# USB0_COMMON_0_VBP2APB_WRAP_CONTROLLER_VBP_CORE_ADDR_MAP register map
Vendor: Texas Instruments
Registers are 32-bit, access per field, reset 0x0 unless marked. A register's access mark holds for its fields unless they carry their own. Offsets are as the file gives them; [hi:lo] are bit positions.

## USB0_COMMON_0_VBP2APB_WRAP_CONTROLLER_VBP_CORE_ADDR_MAP (part 6 of 8)
0x1EC VBP2APB_WRAP__CONTROLLER_VBP__CORE_ADDR_MAP_cfg_reg52 reset 0x16000
  [16:0] TWTREV_CNT rw — TWTREV: Time a high-speed capable device operating in high-speed must wait after start of SE0 before reverting to full-speed. Resolution of this parameter is 33.3 ns. For simulation purposes it is recommended to set the value 90112 [~3ms] For synthesis purposes it is recommended to set the value 90112 [~3ms]
0x1F0 VBP2APB_WRAP__CONTROLLER_VBP__CORE_ADDR_MAP_cfg_reg53 reset 0x5C00
  [14:0] TWTRSTHS_CNT rw — TWTRSTHS: Time a device must wait after reverting to full-speed before sampling the bus state for SE0 and beginning the high-speed detection handshake. Resolution of this parameter is 33.3 ns. For simulation purposes it is recommended to set the value 23552 [~785us] For synthesis purposes it is recommended to set the value 23552 [~785us]
0x1F4 VBP2APB_WRAP__CONTROLLER_VBP__CORE_ADDR_MAP_cfg_reg54 reset 0x24A00
  [17:0] TWTRSM_CNT rw — TWTRSM: Period of idle bus before device can initiate resume. Resolution of this parameter is 33.3 ns. For simulation purposes it is recommended to set the value 150016 [~5ms] For synthesis purposes it is recommended to set the value 150016 [~5ms]
0x1F8 VBP2APB_WRAP__CONTROLLER_VBP__CORE_ADDR_MAP_cfg_reg55 reset 0x8000
  [15:0] TDRSMUP_CNT rw — TDRSMUP: Duration of driving resume upstream. Resolution of this parameter is 33.3 ns. For simulation purposes it is recommended to set the value 32768 [~1.1ms] For synthesis purposes it is recommended to set the value 32768 [~1.1ms]
0x1FC VBP2APB_WRAP__CONTROLLER_VBP__CORE_ADDR_MAP_cfg_reg56 reset 0x30
  [5:0] TOUTHS_CNT rw — Time after device expecting a response to a transmission will timeout the transaction. Resolution of this parameter is 33.3 ns. For simulation purposes it is recommended to set the value 48 [~1.6us] For synthesis purposes it is recommended to set the value 48 [~1.6us]
0x200 VBP2APB_WRAP__CONTROLLER_VBP__CORE_ADDR_MAP_cfg_reg57 reset 0x2
  [1:0] LFPS_DEB_WIDTH rw — LFPS_DEB_WIDTH value This parameter defines the LFPS debouncer delay. Only two values are allowed: 0x1 or 0x2. For simulation purposes it is recommended to set the value 1. For synthesis purposes it is recommended to set the value 2.
0x204 VBP2APB_WRAP__CONTROLLER_VBP__CORE_ADDR_MAP_cfg_reg58 reset 0x3D090
  [17:0] LFPS_GEN_U2EXIT rw — LFPS_GEN_U2EXIT value Resolution of this parameter is 8 ns. For simulation purposes it is recommended to set the value 62500 [~500us] For synthesis purposes it is recommended to set the value 250000 [~2ms]
0x208 VBP2APB_WRAP__CONTROLLER_VBP__CORE_ADDR_MAP_cfg_reg59 reset 0x30D4
  [15:0] LFPS_MIN_GEN_U3EXIT rw — LFPS_MIN_GEN_U3EXIT value Resolution of this parameter is 8 ns. For simulation purposes it is recommended to set the value 12500 [~100us] For synthesis purposes it is recommended to set the value 12500 [~100us]
0x20C VBP2APB_WRAP__CONTROLLER_VBP__CORE_ADDR_MAP_cfg_reg60 reset 0x15
  [6:0] PORT_CONFIG_TIMEOUT rw — PORT_CONFIG_TIMEOUT value Resolution of this parameter is 1 us. For simulation purposes it is recommended to set the value 21 [~20us] For synthesis purposes it is recommended to set the value 21 [~20us]
0x210 VBP2APB_WRAP__CONTROLLER_VBP__CORE_ADDR_MAP_cfg_reg61 reset 0xFA
  [10:0] LFPS_POL_LFPS_TO_RXEQ rw — LFPS_POL_LFPS_TO_RXEQ value Resolution of this parameter is 8 ns. For simulation purposes it is recommended to set the value 250 [~2us] For synthesis purposes it is recommended to set the value 250 [~2us]
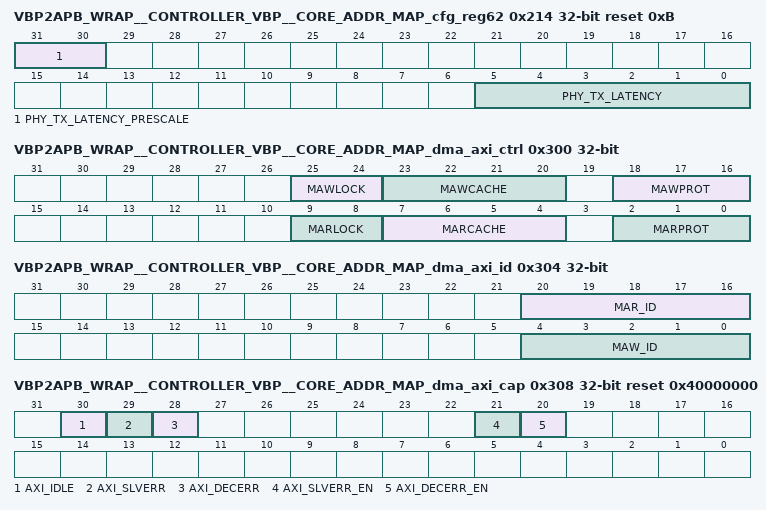
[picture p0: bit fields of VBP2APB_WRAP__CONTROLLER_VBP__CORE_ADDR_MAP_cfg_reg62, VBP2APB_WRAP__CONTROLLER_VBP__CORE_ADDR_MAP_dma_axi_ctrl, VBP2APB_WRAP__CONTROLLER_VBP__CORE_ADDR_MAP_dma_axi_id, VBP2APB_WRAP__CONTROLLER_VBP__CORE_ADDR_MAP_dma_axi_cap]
0x214 VBP2APB_WRAP__CONTROLLER_VBP__CORE_ADDR_MAP_cfg_reg62 reset 0xB
  [31:30] PHY_TX_LATENCY_PRESCALE rw — PRESCALER for PHY_TX_LATENCY value: - 0x0 : 8ns [PHY pclk clock] - 0x1 : 1us - 0x2 : 100us - 0x3 : no clock - allows disabling certain timeout
  [5:0] PHY_TX_LATENCY rw — PHY_TX_LATENCY value This parameter defines latency from when data appear on PIPE interface to channel + 3 time units [defined by PHY_TX_LATENCY_PRESCALE]. For simulation purposes it is recommended to set the value 11. For synthesis purposes it is recommended to set the value 11
0x218 VBP2APB_WRAP__CONTROLLER_VBP__CORE_ADDR_MAP_cfg_reg63 reset 0x7CFF
  [14:0] U2_INACTIVITY_TMOUT rw — U2_INACTIVITY_TMOUT value Resolution of this parameter is 8 ns. For simulation purposes it is recommended to set the value: - 31999*8ns =~256us [SystemC device ENV] - 249*8ns =~2us [VIP based ENV] For synthesis purposes it is recommended to set the value: - 31999*8ns =~256us
0x220 VBP2APB_WRAP__CONTROLLER_VBP__CORE_ADDR_MAP_cfg_reg64 reset 0x4A
  [6:0] TFILTSE0 rw — TFILTSE0: Reset Handshake Protocol: Time for which a suspended highspeed capable device must see a continuous SE0 before beginning the high-speed detection handshake. Resolution of this parameter is 33.3ns. For simulation purposes it is recommended to set the value: - 74*33.3ns =~2.46us [SystemC device ENV] - 57*33.3ns =~1.9us [VIP based ENV] For synthesis purposes it is recommended to set the value: - 74*33.3ns =~2.46us
0x224 VBP2APB_WRAP__CONTROLLER_VBP__CORE_ADDR_MAP_cfg_reg65 reset 0x4B
  [6:0] TFILT rw — TFILT: Time for which a Chirp J or Chirp K must be continuously detected [filtered] by hub or device during Reset handshake. Resolution of this parameter is 33.3 ns. For simulation purposes it is recommended to set the value: - 75*33.3ns =~2.5us [SystemC device ENV] - 57*33.3ns =~1.9us [VIP based ENV] For synthesis purposes it is recommended to set the value: - 75*33.3ns =~2.5us
0x228 VBP2APB_WRAP__CONTROLLER_VBP__CORE_ADDR_MAP_cfg_reg66 reset 0x49
  [6:0] TWTRSTFS_SE0 rw — TWTRSTFS: Time a high-speed capable device operating in non-suspended fullspeed must wait after start of SE0 before beginning the high-speed detection handshake. Resolution of this parameter is 33.3 ns. For simulation purposes it is recommended to set the value: - 73*33.3ns =~2.43us [SystemC device ENV] - 57*33.3ns =~1.9us [VIP based ENV] For synthesis purposes it is recommended to set the value: - 73*33.3ns =~2.43us
0x300 VBP2APB_WRAP__CONTROLLER_VBP__CORE_ADDR_MAP_dma_axi_ctrl
  [25:24] MAWLOCK rw — The mawlock pin configuration
  [23:20] MAWCACHE rw — The mawcache pin configuration
  [18:16] MAWPROT rw — The mawprot pin configuration
  [9:8] MARLOCK rw — The marlock pin configuration
  [7:4] MARCACHE rw — The marcache pin configuration
  [2:0] MARPROT rw — The marprot pin configuration
0x304 VBP2APB_WRAP__CONTROLLER_VBP__CORE_ADDR_MAP_dma_axi_id
  [20:16] MAR_ID rw — The marid pin configuration
  [4:0] MAW_ID rw — The mawid and mwid pin configuration
0x308 VBP2APB_WRAP__CONTROLLER_VBP__CORE_ADDR_MAP_dma_axi_cap access not given reset 0x40000000
  [30] AXI_IDLE ro — This bit provides information about the AXI Master state: '1': no pending action required by the AXI Master wrapper, '0': the AXI Master wrapper has outstanding transactions.
  [29] AXI_SLVERR — This bit provides an information about AXI SLAVE ERROR response on B or R channel. This flag is cleared by writing '1' to it. Once set it is held until cleared. (access R/W1TC)
  [28] AXI_DECERR — This bit provides an information about AXI DECODE ERROR response on B or R channel. This flag is cleared by writing '1' to it. Once set it is held until cleared. (access R/W1TC)
  [21] AXI_SLVERR_EN rw — This bit enables interrupt on AXI SLAVE ERROR detection. When 1 and AXI_SLVERR is 1 then AXI SLAVE ERROR interrupt is requested. When 0 - disabled interrupt from this source
  [20] AXI_DECERR_EN rw — This bit enables interrupt on AXI DECODE ERROR detection. When 1 and AXI_DECERR is 1 then AXI DECODE ERROR interrupt is requested. When 0 - disabled interrupt from this source
0x30C VBP2APB_WRAP__CONTROLLER_VBP__CORE_ADDR_MAP_dma_axi_ctrl0 reset 0xF
  [3:0] B_MAX rw — The register controls maximum burst length - it is used by the AXI Master wrapper to determine maximum value of AxLEN. It uses AXI AxLEN encoding. Default value is the maximum supported one and it is implementation specific. Width of this register is the same as AxLEN signals width. Note: This register should only be written to during the register initialisation process
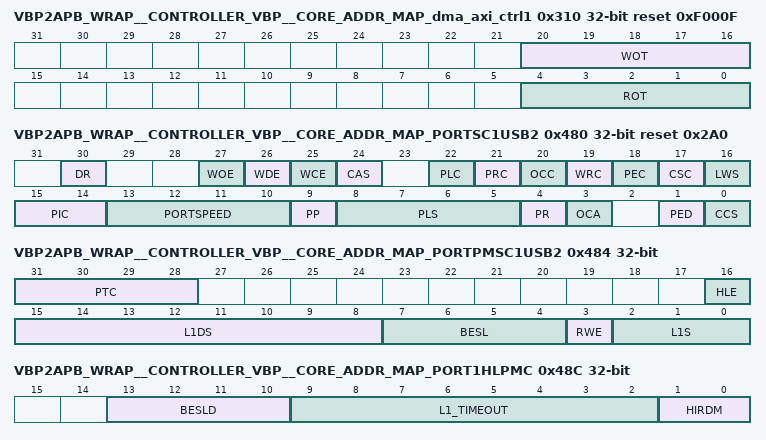
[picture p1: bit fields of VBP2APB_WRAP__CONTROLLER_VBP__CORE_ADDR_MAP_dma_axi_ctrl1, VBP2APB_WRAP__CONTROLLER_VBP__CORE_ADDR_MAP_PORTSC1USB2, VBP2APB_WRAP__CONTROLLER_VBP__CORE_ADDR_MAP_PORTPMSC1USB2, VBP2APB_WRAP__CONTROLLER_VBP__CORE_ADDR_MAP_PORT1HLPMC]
0x310 VBP2APB_WRAP__CONTROLLER_VBP__CORE_ADDR_MAP_dma_axi_ctrl1 reset 0xF000F
  [20:16] WOT rw — Number of outstanding write transactions that can be initiated by the AXI Master wrapper. Default value of this field is CDNS_USBSSDEV_AXI_WCD-1 [define parameter]. The value written to this field should be the requested number of outstanding write transactions minus 1, thus the actual number of possible outstanding write transactions is one more than the programmed value. Note: This register should only be written to during the register initialization process
  [4:0] ROT rw — Number of outstanding read transactions that can be initiated by the AXI Master wrapper. Default value of this field is CDNS_USBSSDEV_AXI_WCD-1 [define parameter]. The value written to this field should be the requested number of outstanding read transactions minus 1, thus the actual number of possible outstanding read transactions is one more than the programmed value. Note: This register should only be written to during the register initialization process
0x314 VBP2APB_WRAP__CONTROLLER_VBP__CORE_ADDR_MAP_dma_axi_ctrl2 reset 0x1
  [6:0] AXI_WTHRES rw — AXI Write Buffer Threshold, RW. When performing an AXI write burst this field specifies the minimum number of required AXI beats buffered prior to starting the burst on AXI W-Channel by asserting wvalid. This allows a user to balance the requirement for minimal latency with the requirement for low bus utilisation during bursts. Burst lengths smaller than or equal to this threshold will be buffered completely and then output on W-Channel. Burst lengths greater than this threshold will output the burst on the W-Channel such that the first AXI_WTHRES beats will be continuously with no drop of WVALID, beats thereafter may or may not be continuous depending on availability of data. Legal values are between 1 and 127. A value of 1 means that the burst is started on W-Channel as soon as any data is available without any additional delay. A value of 0 is reserved and should not be used as may lead to unpredictable behaviour. This register can be written only when the AXI Master wrapper is halted [AXI_HALT set to '1'] and idle [AXI_IDLE is '1']. Note: This register should only be written to during the register initialisation process.
0x480 VBP2APB_WRAP__CONTROLLER_VBP__CORE_ADDR_MAP_PORTSC1USB2 access not given reset 0x2A0
  [30] DR ro — Device Removable [DR], RO. This flag indicates if this port has a removable device attached. '0' = Device is removable. '1' = Device is non-removable.
  [27] WOE rw — Wake on Over-current Enable [WOE], RWS. Default = '0'. Writing this bit to a '1' enables the port to be sensitive to over-current conditions as system wake-up events. Refer to section 4.15 of xHCI specification for operational model.
  [26] WDE rw — Wake on Disconnect Enable [WDE], RWS. Default = '0'. Writing this bit to a '1' enables the port to be sensitive to device disconnects as system wake-up events. Refer to section 4.15 of xHCI specification for operational model.
  [25] WCE rw — Wake on Connect Enable [WCE], RWS. Default = '0'. Writing this bit to a '1' enables the port to be sensitive to device connects as system wake-up events. Refer to section 4.15 of xHCI specification for operational model.
  [24] CAS ro — Cold Attach Status [CAS], RO. Default = '0'. '1' = Far-end Receiver Terminations were detected in the Disconnected state and the Root Hub Port State Machine was unable to advance to the Enabled state. Refer to sections 4.19.8 of xHCI specification for more details on the Cold Attach Status [CAS] assertion conditions. Software shall clear this bit by writing a '1' to WPR or the xHC shall clear this bit if CCS transitions to '1'. This flag is '0' for USB2 protocol ports.
  [22] PLC — Port Link State Change [PLC], RW1CS. Default = '0'. This flag is set to '1' due to the following PLS transitions: U3 -> Resume [Wakeup signaling from a device], Resume -> Recovery -> U0 [Device Resume complete [USB3 protocol ports only]], Resume -> U0 [Device Resume complete [USB2 protocol ports only]], U3 -> Recovery -> U0 [Software Resume complete [USB3 protocol ports only]], U3 -> U0 [Software Resume complete [USB2 protocol ports only]], U2 -> U0 [L1 Resume complete [USB2 protocol ports only]], U0 -> U0 [L1 Entry Reject [USB2 protocol ports only]], Any state -> Inactive [Error [USB3 protocol ports only]]. Note that this flag shall not be set if the PLS transition was due to software setting PP to 0. Refer to section 4.23.5 of xHCI specification for more information. '0' = No change. '1' = Link Status Changed. Software shall clear this bit by writing a '1' to it. Refer to PLC Condition: references in section 4.19.1 for the specific port state transitions that set this flag. Refer to section 4.19.2 of xHCI specification for more information on change bit usage. (access R/W1TC)
  [21] PRC — Port Reset Change [PRC], RW1CS. Default = '0'. This flag is set to '1' due to a '1' to '0' transition of Port Reset [PR], e.g. when any reset processing [Warm or Hot] on this port is complete. Note that this flag shall not be set to '1' if the reset processing was forced to terminate due to software clearing PP or PED to '0'. '0' = No change. '1' = Reset complete. Software shall clear this bit by writing a '1' to it. Refer to section 4.19.5 of xHCI specification. Refer to section 4.19.2 of xHCI specification for more information on change bit usage. (access R/W1TC)
  [20] OCC — Over-current Change [OCC], RW1CS. Default = '0'. This bit shall be set to a '1' when there is a '0' to '1' or '1' to '0' transition of Over-current Active [OCA]. Software shall clear this bit by writing a '1' to it. Refer to section 4.19.2 of xHCI specification for more information on change bit usage. (access R/W1TC)
  [19] WRC — Warm Port Reset Change [WRC], RW1CS/RsvdZ. Default = '0'. This bit is set when Warm Reset processing on this port completes. '0' = No change. '1' = Warm Reset complete. Note that this flag shall not be set to '1' if the Warm Reset processing was forced to terminate due to software clearing PP or PED to '0'. Software shall clear this bit by writing a '1' to it. Refer to section 4.19.5.1 of xHCI specification. Refer to section 4.19.2 of xHCI specification for more information on change bit usage. This bit only applies to USB3 protocol ports. For USB2 protocol ports it shall be RsvdZ. (access R/W1TC)
  [18] PEC — Port Enabled/Disabled Change [PEC], RW1CS. Default = '0'. '1' = change in PED. '0' = No change. Note that this flag shall not be set if the PED transition was due to software setting PP to '0'. Software shall clear this bit by writing a '1' to it. Refer to section 4.19.2 of xHCI specification for more information on change bit usage. This bit shall be set to '1' only when the port is disabled due to the appropriate conditions existing at the EOF2 point [refer to section 11.8.1 of the USB2 Specification for the definition of a Port Error]. (access R/W1TC)
  [17] CSC — Connect Status Change [CSC], RW1CS. Default = '0'. '1' = Change in CCS. '0' = No change. This flag indicates a change has occurred in the ports Current Connect Status [CCS] or Cold Attach Status [CAS] bits. Note that this flag shall not be set if the CCS transition was due to software setting PP to '0', or the CAS transition was due to software setting WPR to '1'. The xHC sets this bit to '1' for all changes to the port device connect status, even if system software has not cleared an existing Connect Status Change. For example, the insertion status changes twice before system software has cleared the changed condition, root hub hardware will be setting an already-set bit [i.e., the bit will remain 1]. Software shall clear this bit by writing a '1' to it. Refer to section 4.19.2 of xHCI specification for more information on change bit usage. (access R/W1TC)
  [16] LWS rw — Port Link State Write Strobe [LWS], RW. Default = '0'. When this bit is set to '1' on a write reference to this register, this flag enables writes to the PLS field. When '0', write data in PLS field is ignored. Reads to this bit return '0'.
  [15:14] PIC rw — Port Indicator Control [PIC], RWS. Default = '0'. Writing to these bits has no effect if the Port Indicators [PIND] bit in the HCCPARAMS register is a '0'. If PIND bit is a '1', then the bit encodings are: 0: Port indicators are off, 1: Amber, 2: Green, 3: Undefined. Refer to the USB2 Specification section 11.5.3 for a description on how these bits shall be used. This field is '0' if PP is '0'.
  [13:10] PORTSPEED ro — Port Speed [Port Speed], ROS. Default = '0'. This field identifies the speed of the connected USB Device. This field is only relevant if a device is connected [CCS = '1'] in all other cases this field shall indicate Undefined Speed. Possible values: 0: Undefined Speed 1-15: Protocol Speed ID [PSI], refer to section 7.2.1 of xHCI specification for the definition of PSIV field in the PSI Dword. Note: This field is invalid on a USB2 protocol port until after the port is reset.
  [9] PP rw — Port Power [PP], RWS. Default = '1'. This flag reflects a port's logical, power control state. Because host controllers can implement different methods of port power switching, this flag may or may not represent whether [VBus] power is actually applied to the port. When PP equals a '0' the port is nonfunctional and shall not report attaches, detaches, or Port Link State [PLS] changes. However, the port shall report over-current conditions when PP = '0' if PPC = '0'. After modifying PP, software shall read PP and confirm that it has reached its target state before modifying it again, undefined behavior may occur if this procedure is not followed. '0' = This port is in the Powered-off state. '1' = This port is not in the Powered-off state. If the Port Power Control [PPC] flag in the HCCPARAMS register is '1', then xHC has port power control switches and this bit represents the current setting of the switch ['0' = off, '1'=on]. If the Port Power Control [PPC] flag in the HCCPARAMS register is '0', then xHC does not have port power control switches and each port is hard wired to power, and not affected by this bit. When an over-current condition is detected on a powered port, the xHC shall transition the PP bit in each affected port from a '1' to '0' [removing power from the port]. Refer to section 4.19.4 for more information.
  [8:5] PLS rw — Port Link State [PLS], RWS. Default = RxDetect ['5']. This field is used to power manage the port and reflects its current link state. When the port is in the Enabled state, system software may set the link U state by writing this field. System software may also write this field to force a Disabled to Disconnected state transition of the port. Write Values: 0: The link shall transition to a U0 state from any of the U states. 2: The link should transition to the U2 State. 3: The link shall transition to a U3 state from the U0 state. This action selectively suspends the device connected to this port. While the Port Link State = U3, the hub does not propagate downstream-directed traffic to this port, but the hub shall respond to resume signaling from the port. 5: USB3 protocol ports only. If the port is in the Disabled state [PLS = Disabled, PP = 1], then the link shall transition to a RxDetect state and the port shall transition to the Disconnected state, else ignored. 10: USB3 protocol ports only. If CTC bit in HCCPARAMS2 is 2, it shall enable a link transition to the Compliance state, i.e. CTE = 1. Refer to section 4.19.1.2.4.1 of xHCI specification for more information. 15: If the port is in the U3 state [PLS = U3], then the link shall remain in the U3 state and the port shall transition to the Resume substate, else ignored. Refer to section 4.15.2 of xHCI specification for more information. others: Ignored. State Encoding: 0: Link is in the U0 State, 1: Link is in the U1 State, 2: Link is in the U2 State, 3: Link is in the U3 State [Device Suspended], 4: Link is in the Disabled State, 5: Link is in the RxDetect State, 6: Link is in the Inactive State, 7: Link is in the Polling State, 8: Link is in the Recovery State, 9: Link is in the Hot Reset State, 10 Link is in the Compliance Mode State, 11: Link is in the Test Mode State, 12-14: Reserved, 15: Link is in the Resume State. Note: The Port Link State Write Strobe [LWS] shall also be set to '1' to write this field. This field is undefined if PP = '0'. Writing a value of '2' to this field shall request LPM, asserting L1 signaling on the USB2 bus. Software may read this field to determine if the transition to the U2 state was successful. Writing a value of '0' shall deassert L1 signaling on the USB. Writing a value of '1' shall have no effect. The U1 state shall never be reported by a USB2 protocol port. Note: Transitions between different states are not reflected until the transition is complete. Refer to section 4.19 of xHCI specification for PLS transition conditions. Refer to sections 4.15.2 and 4.23.5 for more information on the use of this field. Refer to the USB2 LPM ECR for more information on USB link power management operation.
  [4] PR — Port Reset [PR], RW1S. Default = '0'. '1' = Port Reset signaling is asserted. '0' = Port is not in Reset. When software writes a '1' to this bit generating a '0' to '1' transition, the bus reset sequence is initiated. USB2 protocol ports shall execute the bus reset sequence as defined in the USB2 Spec. PR remains set until reset signaling is completed by the root hub. Note that software shall write a '1' to this flag to transition a USB2 port from the Polling state to the Enabled state. Refer to sections 4.15.2.3 and 4.19.1.1 of xHCI specification. This flag is '0' if PP is '0'. (access R/W1TS)
  [3] OCA ro — Over-current Active [OCA], RO. Default = '0'. '1' = This port currently has an over-current condition. '0' = This port does not have an over-current condition. This bit shall automatically transition from a '1' to a '0' when the over-current condition is removed.
  [1] PED — Port Enabled/Disabled [PED], RW1CS. Default = '0'. '1' = Enabled. '0' = Disabled. Ports may only be enabled by the xHC. Software cannot enable a port by writing a '1' to this flag. A port may be disabled by software writing a '1' to this flag. This flag shall automatically be cleared to '0' by a disconnect event or other fault condition. Note that the bit status does not change until the port state actually changes. There may be a delay in disabling or enabling a port due to other host controller or bus events. When the port is disabled [PED = '0'] downstream propagation of data is blocked on this port, except for reset. When the port is in the Disabled state, software shall reset the port [PR = '1'] to transition PED to '1' and the port to the Enabled state. Note that when software writes this bit to a '1', it shall also write a '0' to the PR bit. This flag is '0' if PP is '0'. (access R/W1TC)
  [0] CCS ro — Current Connect Status [CCS], ROS. Default = '0'. '1' = A device is connected to the port. '0' = A device is not connected. This value reflects the current state of the port, and may not correspond directly to the event that caused the Connect Status Change [CSC] bit to be set to '1'. Refer to sections 4.19.3 and 4.19.4 of xHCI specification for more details on the Connect Status Change [CSC] assertion conditions. This flag is '0' if PP is '0'.
0x484 VBP2APB_WRAP__CONTROLLER_VBP__CORE_ADDR_MAP_PORTPMSC1USB2
  [31:28] PTC rw — Port Test Control, RW. Default = '0'. When this field is '0', the port is NOT operating in a test mode. A non-zero value indicates that it is operating in test mode and the specific test mode is indicated by the specific value. A non-zero Port Test Control value is only valid to a port that is in the Powered-Off state [PLS = Disabled]. If the port is not in this state, the xHC shall respond with the Port Test Control field set to Port Test Control Error. Refer to section 4.19.6 for the operational model for using these test modes. The encoding of the Test Mode bits for a USB2 protocol port are: 0: Test mode not enabled 1: Test J_STATE 2: Test K_STATE 3: Test SE0_NAK 4: Test Packet 5: Test FORCE_ENABLE 6-14: Reserved. 15: Port Test Control Error. Refer to the sections 7.1.20 and 11.24.2.13 of the USB2 spec for more information on Test Modes.
  [16] HLE rw — Hardware LPM Enable [HLE], RW. Default = '0'. If this bit is set to '1', then hardware controlled LPM shall be enabled for this port. Refer to section 4.23.5.1.1.1 of xHCI specification. If the USB2 Hardware LPM Capability is not supported [HLC = '0'] this field shall be RsvdZ.
  [15:8] L1DS rw — L1 Device Slot, RW. Default = 0. System software sets this field to indicate the ID of the Device Slot associated with the device directly attached to the Root Hub port. A value of '0' indicates no device is present. The xHC uses this field to lookup information necessary to generate the LPM Token packet.
  [7:4] BESL rw — Best Effort Service Latency [BESL], RW. Default = 0. System software sets this field to indicate to the recipient device how long the xHC will drive resume if it [the xHC] initiates an exit from L1. The BESL value encoding is defined in Table 13. Note that the BESL field is used by both software and hardware controlled LPM. Refer to section 4.23.5.1.1 of xHCI specification for more information on BESL use. Refer to section 5.2.5 of xHCI specification for information on how DBESL may be used to establish an initial value for BESL.
  [3] RWE rw — Remote Wake Enable [RWE], RW. Default = '0'. System software sets this flag to enable or disable the device for remote wake from L1. The value of this flag shall temporarily [while in L1] override the current setting of the Remote Wake feature set by the standard Set/ClearFeature[] commands defined in Universal Serial Bus Specification, revision 2.0, Chapter 9.
  [2:0] L1S ro — L1 Status [L1S], RO. Default = 0. This field is used by software to determine whether an L1-based suspend request [LPM transaction] was successful, specifically: 0: Invalid - This field shall be ignored by software. 1: Success - Port successfully transitioned to L1 [ACK] 2: Not Yet - Device is unable to enter L1 at this time [NYET] 3: Not Supported - Device does not support L1 transitions [STALL] 4: Timeout/Error - Device failed to respond to the LPM Transaction or an error occurred 5-7: Reserved The value of this field is only valid when the port resides in the L0 or L1 state [PLS = 0 or 2]. Refer to section 4.23.5.1.1 of xHCI specification for more information.
0x488 VBP2APB_WRAP__CONTROLLER_VBP__CORE_ADDR_MAP_RSVDP1USB2 ro
0x48C VBP2APB_WRAP__CONTROLLER_VBP__CORE_ADDR_MAP_PORT1HLPMC
  [13:10] BESLD rw — Best Effort Service Latency Deep [BESLD], RWS. Default = '0'. System software sets this field to indicate to the recipient device how long the xHC will drive resume on an exit from U2. Refer to section 4.23.5.1.1.1 of xHCI specification for more information on BESLD use. The BESLD value encoding is defined in Table 13. Refer to section 5.2.6 of xHCI specification for information on how DBESLD may be used to establish an initial value for BESLD.
  [9:2] L1_TIMEOUT rw — L1 Timeout, RWS. Default = 00h. Timeout value for the L1 inactivity timer [LPM Timer]. This field shall be set to 00h by the assertion of PR to '1'. Refer to section 4.23.5.1.1.1 of xHci specification for more information on L1 Timeout operation. The following are permissible values: 00h 128 us. [default] 01h 256 us. 02h 512 us. 03h 768 us. ... FFh 65,280 us.
  [1:0] HIRDM rw — Host Initiated Resume Duration Mode [HIRDM], RWS. Default = 0h. Indicates which HIRD value should be used. The following are permissible values: 0: Initiate L1 using BESL only on timeout. [default] 1: Initiate L1 using BESLD on timeout. If rejected by device, initiate L1 using BESL. 3-2: Reserved.
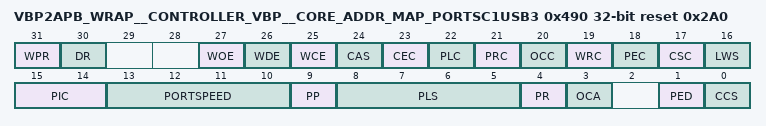
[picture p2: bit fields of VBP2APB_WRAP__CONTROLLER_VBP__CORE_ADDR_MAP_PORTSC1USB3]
0x490 VBP2APB_WRAP__CONTROLLER_VBP__CORE_ADDR_MAP_PORTSC1USB3 access not given reset 0x2A0
  [31] WPR — Warm Port Reset [WPR], RW1S. Default = '0'. When software writes a '1' to this bit, the Warm Reset sequence as defined in the USB3 Specification is initiated and the PR flag is set to '1'. Once initiated, the PR, PRC, and WRC flags shall reflect the progress of the Warm Reset sequence. This flag shall always return 0 when read. Refer to section 4.19.5.1 of xHCI specification. (access R/W1TS)
  [30] DR ro — Device Removable [DR], RO. This flag indicates if this port has a removable device attached. '0' = Device is removable. '1' = Device is non-removable.
  [27] WOE rw — Wake on Over-current Enable [WOE], RWS. Default = '0'. Writing this bit to a '1' enables the port to be sensitive to over-current conditions as system wake-up events. Refer to section 4.15 of xHCI specification for operational model.
  [26] WDE rw — Wake on Disconnect Enable [WDE], RWS. Default = '0'. Writing this bit to a '1' enables the port to be sensitive to device disconnects as system wake-up events. Refer to section 4.15 of xHCI specification for operational model.
  [25] WCE rw — Wake on Connect Enable [WCE], RWS. Default = '0'. Writing this bit to a '1' enables the port to be sensitive to device connects as system wake-up events. Refer to section 4.15 of xHCI specification for operational model.
  [24] CAS ro — Cold Attach Status [CAS], RO. Default = '0'. '1' = Far-end Receiver Terminations were detected in the Disconnected state and the Root Hub Port State Machine was unable to advance to the Enabled state. Refer to sections 4.19.8 of xHCI specification for more details on the Cold Attach Status [CAS] assertion conditions. Software shall clear this bit by writing a '1' to WPR or the xHC shall clear this bit if CCS transitions to '1'. This flag is 0 if PP is 0 or for USB2 protocol ports. Note: Additionally to the xHCI spec the CAS may be set in D1/D2 state. If customer's PLL lock time ensures finishing LFPS in tPollingLFPSTimeout [360ms] the SW driver may ignore the CAS and wait for PORTSC.CCS. It prevents additional reset on USB port. However, handling CAS in normal way should not have any negative impact on the device.
  [23] CEC — Port Config Error Change [CEC], RW1CS. Default = '0'. This flag indicates that the port failed to configure its link partner. '0' = No change. '1' = Port Config Error detected. Software shall clear this bit by writing a '1' to it. Refer to section 4.19.2 of xHCI specification for more information on change bit usage. (access R/W1TC)
  [22] PLC — Port Link State Change [PLC], RW1CS. Default = '0'. This flag is set to '1' due to the following PLS transitions: U3 -> Resume [Wakeup signaling from a device], Resume -> Recovery -> U0 [Device Resume complete [USB3 protocol ports only]], Resume -> U0 [Device Resume complete [USB2 protocol ports only]], U3 -> Recovery -> U0 [Software Resume complete [USB3 protocol ports only]], U3 -> U0 [Software Resume complete [USB2 protocol ports only]], U2 -> U0 [L1 Resume complete [USB2 protocol ports only]], U0 -> U0 [L1 Entry Reject [USB2 protocol ports only]], Any state -> Inactive [Error [USB3 protocol ports only]]. Note that this flag shall not be set if the PLS transition was due to software setting PP to 0. Refer to section 4.23.5 of xHCI specification for more information. '0' = No change. '1' = Link Status Changed. Software shall clear this bit by writing a '1' to it. Refer to PLC Condition: references in section 4.19.1 for the specific port state transitions that set this flag. Refer to section 4.19.2 of xHCI specification for more information on change bit usage. (access R/W1TC)
  [21] PRC — Port Reset Change [PRC], RW1CS. Default = '0'. This flag is set to '1' due to a '1' to '0' transition of Port Reset [PR], e.g. when any reset processing [Warm or Hot] on this port is complete. Note that this flag shall not be set to '1' if the reset processing was forced to terminate due to software clearing PP or PED to '0'. '0' = No change. '1' = Reset complete. Software shall clear this bit by writing a '1' to it. Refer to section 4.19.5 of xHCI specification. Refer to section 4.19.2 of xHCI specification for more information on change bit usage. (access R/W1TC)
  [20] OCC — Over-current Change [OCC], RW1CS. Default = '0'. This bit shall be set to a '1' when there is a '0' to '1' or '1' to '0' transition of Over-current Active [OCA]. Software shall clear this bit by writing a '1' to it. Refer to section 4.19.2 of xHCI specification for more information on change bit usage. (access R/W1TC)
  [19] WRC — Warm Port Reset Change [WRC], RW1CS. Default = '0'. This bit is set when Warm Reset processing on this port completes. '0' = No change. '1' = Warm Reset complete. Note that this flag shall not be set to '1' if the Warm Reset processing was forced to terminate due to software clearing PP or PED to '0'. Software shall clear this bit by writing a '1' to it. Refer to section 4.19.5.1 of xHCI specification. Refer to section 4.19.2 of xHCI specification for more information on change bit usage. (access R/W1TC)
  [18] PEC — Port Enabled/Disabled Change [PEC], RW1CS. Default = '0'. '1' = change in PED. '0' = No change. Note that this flag shall not be set if the PED transition was due to software setting PP to '0'. Software shall clear this bit by writing a '1' to it. Refer to section 4.19.2 of xHCI specification for more information on change bit usage. This bit shall never be set to '1'. (access R/W1TC)
  [17] CSC — Connect Status Change [CSC], RW1CS. Default = '0'. '1' = Change in CCS. '0' = No change. This flag indicates a change has occurred in the ports Current Connect Status [CCS] or Cold Attach Status [CAS] bits. Note that this flag shall not be set if the CCS transition was due to software setting PP to '0', or the CAS transition was due to software setting WPR to '1'. The xHC sets this bit to '1' for all changes to the port device connect status, even if system software has not cleared an existing Connect Status Change. For example, the insertion status changes twice before system software has cleared the changed condition, root hub hardware will be setting an already-set bit [i.e., the bit will remain 1]. Software shall clear this bit by writing a '1' to it. Refer to section 4.19.2 of xHCI specification for more information on change bit usage. (access R/W1TC)
  [16] LWS rw — Port Link State Write Strobe [LWS], RW. Default = '0'. When this bit is set to '1' on a write reference to this register, this flag enables writes to the PLS field. When '0', write data in PLS field is ignored. Reads to this bit return '0'.
  [15:14] PIC rw — Port Indicator Control [PIC], RWS. Default = '0'. Writing to these bits has no effect if the Port Indicators [PIND] bit in the HCCPARAMS register is a '0'. If PIND bit is a '1', then the bit encodings are: 0: Port indicators are off, 1: Amber, 2: Green, 3: Undefined. This field is '0' if PP is '0'.
  [13:10] PORTSPEED ro — Port Speed [Port Speed], ROS. Default = '0'. This field identifies the speed of the connected USB Device. This field is only relevant if a device is connected [CCS = '1'] in all other cases this field shall indicate Undefined Speed. Possible values: 0: Undefined Speed 1-15: Protocol Speed ID [PSI], refer to section 7.2.1 of xHCI specification for the definition of PSIV field in the PSI Dword.
  [9] PP rw — Port Power [PP], RWS. Default = '1'. This flag reflects a port's logical, power control state. Because host controllers can implement different methods of port power switching, this flag may or may not represent whether [VBus] power is actually applied to the port. When PP equals a '0' the port is nonfunctional and shall not report attaches, detaches, or Port Link State [PLS] changes. However, the port shall report over-current conditions when PP = '0' if PPC = '0'. After modifying PP, software shall read PP and confirm that it has reached its target state before modifying it again, undefined behavior may occur if this procedure is not followed. '0' = This port is in the Powered-off state. '1' = This port is not in the Powered-off state. If the Port Power Control [PPC] flag in the HCCPARAMS register is '1', then xHC has port power control switches and this bit represents the current setting of the switch ['0' = off, '1'=on]. If the Port Power Control [PPC] flag in the HCCPARAMS register is '0', then xHC does not have port power control switches and each port is hard wired to power, and not affected by this bit. When an over-current condition is detected on a powered port, the xHC shall transition the PP bit in each affected port from a '1' to '0' [removing power from the port]. Refer to section 4.19.4 for more information.
  [8:5] PLS rw — Port Link State [PLS], RWS. Default = RxDetect ['5']. This field is used to power manage the port and reflects its current link state. When the port is in the Enabled state, system software may set the link U state by writing this field. System software may also write this field to force a Disabled to Disconnected state transition of the port. Write Values: 0: The link shall transition to a U0 state from any of the U states. 3: The link shall transition to a U3 state from the U0 state. This action selectively suspends the device connected to this port. While the Port Link State = U3, the hub does not propagate downstream-directed traffic to this port, but the hub shall respond to resume signaling from the port. 5: If the port is in the Disabled state [PLS = Disabled, PP = '1'], then the link shall transition to a RxDetect state and the port shall transition to the Disconnected state, else ignored. 1-2,4,6-15: Ignored. State Encoding: 0: Link is in the U0 State, 1: Link is in the U1 State, 2: Link is in the U2 State, 3: Link is in the U3 State [Device Suspended], 4: Link is in the Disabled State, 5: Link is in the RxDetect State, 6: Link is in the Inactive State, 7: Link is in the Polling State, 8: Link is in the Recovery State, 9: Link is in the Hot Reset State, 10 Link is in the Compliance Mode State, 11: Link is in the Test Mode State, 12-14: Reserved, 15: Link is in the Resume State. Note: The Port Link State Write Strobe [LWS] shall also be set to '1' to write this field. This field is undefined if PP = '0'. Note: Transitions between different states are not reflected until the transition is complete. Refer to section 4.19 of xHCI specification for PLS transition conditions. Refer to sections 4.15.2 and 4.23.5 for more information on the use of this field.
  [4] PR — Port Reset [PR], RW1S. Default = '0'. '1' = Port Reset signaling is asserted. '0' = Port is not in Reset. When software writes a '1' to this bit generating a '0' to '1' transition, the bus reset sequence is initiated. USB3 protocol ports shall execute the Hot Reset sequence as defined in the USB3 Spec. PR remains set until reset signaling is completed by the root hub. This flag is '0' if PP is '0'. (access R/W1TS)
  [3] OCA ro — Over-current Active [OCA], RO. Default = '0'. '1' = This port currently has an over-current condition. '0' = This port does not have an over-current condition. This bit shall automatically transition from a '1' to a '0' when the over-current condition is removed.
  [1] PED — Port Enabled/Disabled [PED], RW1CS. Default = '0'. '1' = Enabled. '0' = Disabled. Ports may only be enabled by the xHC. Software cannot enable a port by writing a '1' to this flag. A port may be disabled by software writing a '1' to this flag. This flag shall automatically be cleared to '0' by a disconnect event or other fault condition. Note that the bit status does not change until the port state actually changes. There may be a delay in disabling or enabling a port due to other host controller or bus events. When the port is disabled [PED = '0'] downstream propagation of data is blocked on this port, except for reset. When the port is in the Polling state [after detecting an attach], the port shall automatically transition to the Enabled state and set PED to '1' upon the completion of successful link training. When the port is in the Disabled state, software shall write a 5 [RxDetect] to the PLS field to transition the port to the Disconnected state. Refer to section 4.19.1.2 of xHCI specification. PED shall automatically be cleared to '0' when PR is set to '1', and set to '1' when PR transitions from '1' to '0' after a successful reset. Refer to Port Reset [PR] bit for more information on how the PED bit is managed. Note that when software writes this bit to a '1', it shall also write a '0' to the PR bit. This flag is '0' if PP is '0'. (access R/W1TC)
  [0] CCS ro — Current Connect Status [CCS], ROS. Default = '0'. '1' = A device is connected to the port. '0' = A device is not connected. This value reflects the current state of the port, and may not correspond directly to the event that caused the Connect Status Change [CSC] bit to be set to '1'. Refer to sections 4.19.3 and 4.19.4 of xHCI specification for more details on the Connect Status Change [CSC] assertion conditions. This flag is '0' if PP is '0'.
